AUTOSAR XML (schema 4-2-2)
package /RootP_ASWC_LPhM
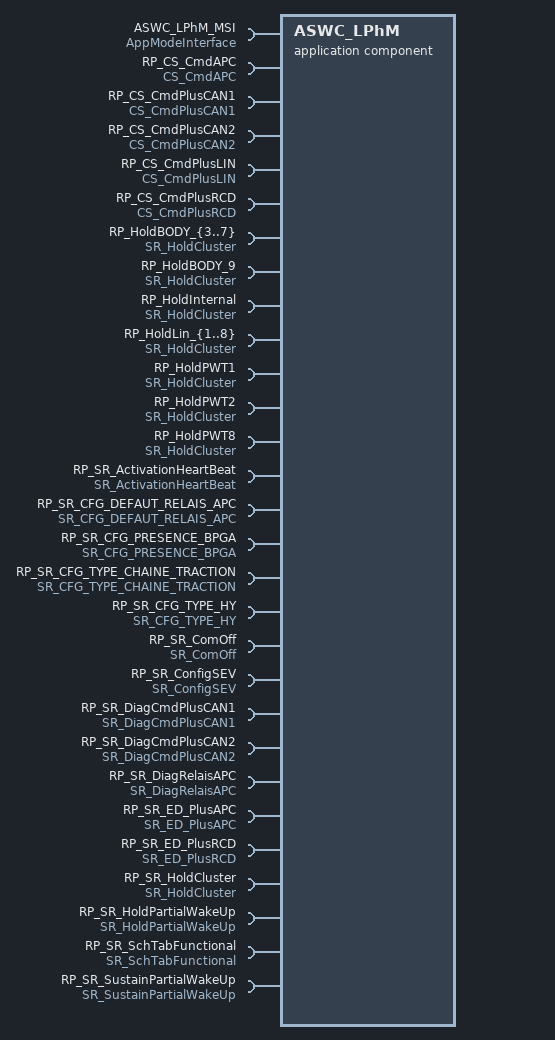
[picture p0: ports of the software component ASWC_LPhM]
  application sw component type ASWC_LPhM
    require port ASWC_LPhM_MSI: required-interface=AppModeInterface
    66 x provide/require port:
      PP_AppModeRequest: nonqueued-receiver-com-spec{data-element=RequestedMode, handle-data-status=true, init-value=CONST_t_ApplicationModeRequestType_0:0}, provided-required-interface=SR_AppModeRequest
      PP_BodyNetworkWkPattern: nonqueued-receiver-com-spec{data-element=CanWkPattern, handle-data-status=true, init-value=CONST_tLOG_0:0}, provided-required-interface=SR_BodyNetworkWkPattern
      PP_BodyVersion: nonqueued-receiver-com-spec{data-element=BodyVersion, handle-data-status=true, init-value=CONST_t_cBodyVersion_0:0}, provided-required-interface=SR_BodyVersion
      PP_ComOffIndicationOnLin: nonqueued-receiver-com-spec{data-element=ComOffIndication, handle-data-status=true, init-value=CONST_ComOffIndication_t_cLIN_COMOFF_cLIN_COMOFFINACTIF:0}, provided-required-interface=SR_ComOffIndicationOnLin
      PP_InhibNetworkWakeUp_CanBody_{3..7}: nonqueued-receiver-com-spec{data-element=NetworkWkInhibition, handle-data-status=true, init-value=CONST_tLOG_0:0}, provided-required-interface=SR_InhibNetworkWakeUp
      PP_InhibNetworkWakeUp_CanBody_9: nonqueued-receiver-com-spec{data-element=NetworkWkInhibition, handle-data-status=true, init-value=CONST_tLOG_0:0}, provided-required-interface=SR_InhibNetworkWakeUp
      PP_InhibPartialWakeUp_CanPwt_1: nonqueued-receiver-com-spec{data-element=PartialWkInhibition, handle-data-status=true, init-value=CONST_tLOG_0:0}, provided-required-interface=SR_InhibPartialWakeUp
      PP_InhibPartialWakeUp_CanPwt_2: nonqueued-receiver-com-spec{data-element=PartialWkInhibition, handle-data-status=true, init-value=CONST_tLOG_0:0}, provided-required-interface=SR_InhibPartialWakeUp
      PP_InhibPartialWakeUp_CanPwt_8: nonqueued-receiver-com-spec{data-element=PartialWkInhibition, handle-data-status=true, init-value=CONST_tLOG_0:0}, provided-required-interface=SR_InhibPartialWakeUp
      PP_LpCanBody_{3..7}: nonqueued-receiver-com-spec{data-element=LpCanBody, handle-data-status=true, init-value=CONST_LpCanBody_t_cLpCanBody_cSGL_BODY_Sleep:0}, provided-required-interface=SR_LpCanBody
      PP_LpCanBody_9: nonqueued-receiver-com-spec{data-element=LpCanBody, handle-data-status=true, init-value=CONST_LpCanBody_t_cLpCanBody_cSGL_BODY_Sleep:0}, provided-required-interface=SR_LpCanBody
      PP_LpLin_{1..8}: nonqueued-receiver-com-spec{data-element=LpLin, handle-data-status=true, init-value=CONST_LpLin_t_cLpLIN_PrepareToSleep:0}, provided-required-interface=SR_LpLin
      PP_NetState_CanBody_{3..7}: nonqueued-receiver-com-spec{data-element=NetState_CanBody, handle-data-status=true, init-value=CONST_NetState_CanBody_t_cCANBODY_cBODY_ComOff:0}, provided-required-interface=SR_NetState_CanBody
      PP_NetState_CanBody_9: nonqueued-receiver-com-spec{data-element=NetState_CanBody, handle-data-status=true, init-value=CONST_NetState_CanBody_t_cCANBODY_cBODY_ComOff:0}, provided-required-interface=SR_NetState_CanBody
      PP_NetState_CanPwt_1: nonqueued-receiver-com-spec{data-element=NetState_CanPwt, handle-data-status=true, init-value=CONST_NetState_CanPwt_t_cCANPWT_cPWT_OFF:0}, provided-required-interface=SR_NetState_CanPwt
      PP_NetState_CanPwt_2: nonqueued-receiver-com-spec{data-element=NetState_CanPwt, handle-data-status=true, init-value=CONST_NetState_CanPwt_t_cCANPWT_cPWT_OFF:0}, provided-required-interface=SR_NetState_CanPwt
      PP_NetState_CanPwt_8: nonqueued-receiver-com-spec{data-element=NetState_CanPwt, handle-data-status=true, init-value=CONST_NetState_CanPwt_t_cCANPWT_cPWT_OFF:0}, provided-required-interface=SR_NetState_CanPwt
      PP_NetState_Lin_{1..8}: nonqueued-receiver-com-spec{data-element=NetState_Lin, handle-data-status=true, init-value=CONST_NetState_Lin_t_cLINLPhM_LIN_SLEEP:0}, provided-required-interface=SR_NetState_Lin
      PP_OpStatusCanPwt_1: nonqueued-receiver-com-spec{data-element=OpStatusCanPwt, handle-data-status=true, init-value=CONST_OpStatusCanPwt_t_cOSPWT_cOSPWT_Default:7}, provided-required-interface=SR_OpStatusCanPwt
      PP_OpStatusCanPwt_2: nonqueued-receiver-com-spec{data-element=OpStatusCanPwt, handle-data-status=true, init-value=CONST_OpStatusCanPwt_t_cOSPWT_cOSPWT_Default:7}, provided-required-interface=SR_OpStatusCanPwt
      PP_OpStatusCanPwt_8: nonqueued-receiver-com-spec{data-element=OpStatusCanPwt, handle-data-status=true, init-value=CONST_OpStatusCanPwt_t_cOSPWT_cOSPWT_Default:7}, provided-required-interface=SR_OpStatusCanPwt
      PRP_SR_AppModeRequest: nonqueued-receiver-com-spec{data-element=RequestedMode, handle-data-status=true, init-value=CONST_t_ApplicationModeRequestType_0:0}, provided-required-interface=SR_AppModeRequest
      PRP_SR_BodyNetworkWkPattern: nonqueued-receiver-com-spec{data-element=CanWkPattern, handle-data-status=true, init-value=CONST_tLOG_0:0}, provided-required-interface=SR_BodyNetworkWkPattern
      PRP_SR_BodyVersion: nonqueued-receiver-com-spec{data-element=BodyVersion, handle-data-status=true, init-value=CONST_t_cBodyVersion_0:0}, provided-required-interface=SR_BodyVersion
      PRP_SR_ComOffIndicationOnLin: nonqueued-receiver-com-spec{data-element=ComOffIndication, handle-data-status=true, init-value=CONST_ComOffIndication_t_cLIN_COMOFF_cLIN_COMOFFINACTIF:0}, provided-required-interface=SR_ComOffIndicationOnLin
      PRP_SR_InhibNetworkWakeUp: nonqueued-receiver-com-spec{data-element=NetworkWkInhibition, handle-data-status=true, init-value=CONST_tLOG_0:0}, provided-required-interface=SR_InhibNetworkWakeUp
      PRP_SR_InhibPartialWakeUp: nonqueued-receiver-com-spec{data-element=PartialWkInhibition, handle-data-status=true, init-value=CONST_tLOG_0:0}, provided-required-interface=SR_InhibPartialWakeUp
      PRP_SR_LastWakeupEvents: nonqueued-receiver-com-spec{data-element=LastWakeupEvents, handle-data-status=true, init-value=CONST_tDWORD_0:0}, provided-required-interface=SR_LastWakeupEvents
      PRP_SR_LpCanBody: nonqueued-receiver-com-spec{data-element=LpCanBody, handle-data-status=true, init-value=CONST_LpCanBody_t_cLpCanBody_cSGL_BODY_Sleep:0}, provided-required-interface=SR_LpCanBody
      PRP_SR_LpLin: nonqueued-receiver-com-spec{data-element=LpLin, handle-data-status=true, init-value=CONST_LpLin_t_cLpLIN_PrepareToSleep:0}, provided-required-interface=SR_LpLin
      PRP_SR_NetState_CanBody: nonqueued-receiver-com-spec{data-element=NetState_CanBody, handle-data-status=true, init-value=CONST_NetState_CanBody_t_cCANBODY_cBODY_ComOff:0}, provided-required-interface=SR_NetState_CanBody
      PRP_SR_NetState_CanPwt: nonqueued-receiver-com-spec{data-element=NetState_CanPwt, handle-data-status=true, init-value=CONST_NetState_CanPwt_t_cCANPWT_cPWT_OFF:0}, provided-required-interface=SR_NetState_CanPwt
      PRP_SR_NetState_Lin: nonqueued-receiver-com-spec{data-element=NetState_Lin, handle-data-status=true, init-value=CONST_NetState_Lin_t_cLINLPhM_LIN_SLEEP:0}, provided-required-interface=SR_NetState_Lin
      PRP_SR_OpStatusCanPwt: nonqueued-receiver-com-spec{data-element=OpStatusCanPwt, handle-data-status=true, init-value=CONST_OpStatusCanPwt_t_cOSPWT_cOSPWT_Default:7}, provided-required-interface=SR_OpStatusCanPwt
      PRP_SR_PwtVersion: nonqueued-receiver-com-spec{data-element=PwtVersion, handle-data-status=true, init-value=CONST_t_cPwtVersion_0:0}, provided-required-interface=SR_PwtVersion
      PRP_SR_StatusCmdAPC: nonqueued-receiver-com-spec{data-element=StatusCmdAPC, handle-data-status=true, init-value=CONST_StatusCmdAPC_t_cCmdAPC_APC_UNDEFINED:0}, provided-required-interface=SR_StatusCmdAPC
      PRP_SR_StatusCmdPlusCAN: nonqueued-receiver-com-spec{data-element=StatusCmdPlusCAN, handle-data-status=true, init-value=CONST_StatusCmdPlusCAN_t_cCmdPlusCAN_PLUSCAN_UNDEFINED:3}, provided-required-interface=SR_StatusCmdPlusCAN
      PRP_SR_StatusCmdPlusLIN: nonqueued-receiver-com-spec{data-element=StatusCmdPlusLIN, handle-data-status=true, init-value=CONST_StatusCmdPlusLIN_t_cCmdPlusLIN_PLUSLIN_UNDEFINED:3}, provided-required-interface=SR_StatusCmdPlusLIN
      PRP_SR_StatusCmdPlusRCD: nonqueued-receiver-com-spec{data-element=StatusCmdPlusRCD, handle-data-status=true, init-value=CONST_StatusCmdPlusRCD_t_cCmdPlusRCD_cPLUSRCD_OFF:0}, provided-required-interface=SR_StatusCmdPlusRCD
      PRP_SR_WakeupCause: nonqueued-receiver-com-spec{data-element=WakeupCause, handle-data-status=true, init-value=CONST_WakeupCause_t_WakeUpCause_cUNKNOWN_SOURCE:0}, provided-required-interface=SR_WakeupCause
    39 x require port:
      RP_CS_CmdAPC: required-interface=CS_CmdAPC
      RP_CS_CmdPlusCAN1: required-interface=CS_CmdPlusCAN1
      RP_CS_CmdPlusCAN2: required-interface=CS_CmdPlusCAN2
      RP_CS_CmdPlusLIN: required-interface=CS_CmdPlusLIN
      RP_CS_CmdPlusRCD: required-interface=CS_CmdPlusRCD
      RP_HoldBODY_{3..7}: nonqueued-receiver-com-spec{data-element=HoldCluster, handle-data-status=true, init-value=CONST_HoldCluster_t_cHOLD_cHOLD_OFF:0}, required-interface=SR_HoldCluster
      RP_HoldBODY_9: nonqueued-receiver-com-spec{data-element=HoldCluster, handle-data-status=true, init-value=CONST_HoldCluster_t_cHOLD_cHOLD_OFF:0}, required-interface=SR_HoldCluster
      RP_HoldInternal: nonqueued-receiver-com-spec{data-element=HoldCluster, handle-data-status=true, init-value=CONST_HoldCluster_t_cHOLD_cHOLD_OFF:0}, required-interface=SR_HoldCluster
      RP_HoldLin_{1..8}: nonqueued-receiver-com-spec{data-element=HoldCluster, handle-data-status=true, init-value=CONST_HoldCluster_t_cHOLD_cHOLD_OFF:0}, required-interface=SR_HoldCluster
      RP_HoldPWT1: nonqueued-receiver-com-spec{data-element=HoldCluster, handle-data-status=true, init-value=CONST_HoldCluster_t_cHOLD_cHOLD_OFF:0}, required-interface=SR_HoldCluster
      RP_HoldPWT2: nonqueued-receiver-com-spec{data-element=HoldCluster, handle-data-status=true, init-value=CONST_HoldCluster_t_cHOLD_cHOLD_OFF:0}, required-interface=SR_HoldCluster
      RP_HoldPWT8: nonqueued-receiver-com-spec{data-element=HoldCluster, handle-data-status=true, init-value=CONST_HoldCluster_t_cHOLD_cHOLD_OFF:0}, required-interface=SR_HoldCluster
      RP_SR_ActivationHeartBeat: nonqueued-receiver-com-spec{data-element=ActivationHeartBeat, handle-data-status=true, init-value=CONST_tLOG_1:1}, required-interface=SR_ActivationHeartBeat
      RP_SR_CFG_DEFAUT_RELAIS_APC: nonqueued-receiver-com-spec{data-element=CFG_DEFAUT_RELAIS_APC, handle-data-status=true, init-value=CONST_tLOG_0:0}, required-interface=SR_CFG_DEFAUT_RELAIS_APC
      RP_SR_CFG_PRESENCE_BPGA: nonqueued-receiver-com-spec{data-element=CFG_PRESENCE_BPGA, handle-data-status=true, init-value=CONST_tLOG_0:0}, required-interface=SR_CFG_PRESENCE_BPGA
      RP_SR_CFG_TYPE_CHAINE_TRACTION: nonqueued-receiver-com-spec{data-element=CFG_TYPE_CHAINE_TRACTION, handle-data-status=true, init-value=CONST_t_cTCT_0:0}, required-interface=SR_CFG_TYPE_CHAINE_TRACTION
      RP_SR_CFG_TYPE_HY: nonqueued-receiver-com-spec{data-element=CFG_TYPE_HY, handle-data-status=true, init-value=CONST_t_H_0:0}, required-interface=SR_CFG_TYPE_HY
      RP_SR_ComOff: nonqueued-receiver-com-spec{data-element=ComOff, handle-data-status=true, init-value=CONST_tLOG_0:0}, required-interface=SR_ComOff
      RP_SR_ConfigSEV: nonqueued-receiver-com-spec{data-element=ConfigSEV, handle-data-status=true, init-value=CONST_ConfigSEV_t_cCSEV_cCSEV_Montage:0}, required-interface=SR_ConfigSEV
      RP_SR_DiagCmdPlusCAN1: nonqueued-receiver-com-spec{data-element=DiagCmdPlusCAN1, handle-data-status=true, init-value=CONST_DiagCmdPlusCAN1_tSDDiag_cSDDiag_DiagOk:0}, required-interface=SR_DiagCmdPlusCAN1
      RP_SR_DiagCmdPlusCAN2: nonqueued-receiver-com-spec{data-element=DiagCmdPlusCAN2, handle-data-status=true, init-value=CONST_DiagCmdPlusCAN2_tSDDiag_cSDDiag_IndispoDiag:2}, required-interface=SR_DiagCmdPlusCAN2
      RP_SR_DiagRelaisAPC: nonqueued-receiver-com-spec{data-element=DiagRelaisAPC, handle-data-status=true, init-value=CONST_tBYTE_0x02:2}, required-interface=SR_DiagRelaisAPC
      RP_SR_ED_PlusAPC: nonqueued-receiver-com-spec{data-element=ED_PlusAPC, handle-data-status=true, init-value=CONST_tLOG_0:0}, required-interface=SR_ED_PlusAPC
      RP_SR_ED_PlusRCD: nonqueued-receiver-com-spec{data-element=ED_PlusRCD, handle-data-status=true, init-value=CONST_tLOG_0:0}, required-interface=SR_ED_PlusRCD
      RP_SR_HoldCluster: nonqueued-receiver-com-spec{data-element=HoldCluster, handle-data-status=true, init-value=CONST_HoldCluster_t_cHOLD_cHOLD_OFF:0}, required-interface=SR_HoldCluster
      RP_SR_HoldPartialWakeUp: required-interface=SR_HoldPartialWakeUp
        required-com-specs:
          data-element=HoldPWT1PartialWakeUp, handle-data-status=true, init-value=CONST_tLOG_0:0
          data-element=HoldPWT2PartialWakeUp, handle-data-status=true, init-value=CONST_tLOG_0:0
          data-element=HoldPWT8PartialWakeUp, handle-data-status=true, init-value=CONST_tLOG_0:0
      RP_SR_SchTabFunctional: required-interface=SR_SchTabFunctional
        required-com-specs:
          data-element=SchTabFunctional_Lin_{1..8}, handle-data-status=true, init-value=CONST_tBYTE_0:0
      RP_SR_SustainPartialWakeUp: required-interface=SR_SustainPartialWakeUp
        required-com-specs:
          data-element=SustainPWT1PartialWakeUp, handle-data-status=true, init-value=CONST_tLOG_0:0
          data-element=SustainPWT2PartialWakeUp, handle-data-status=true, init-value=CONST_tLOG_0:0
          data-element=SustainPWT8PartialWakeUp, handle-data-status=true, init-value=CONST_tLOG_0:0
    behavior IB_ASWC_LPhM: data-type-mapping=ApplicationModeMapping, handle-termination-and-restart=NO-SUPPORT
      data received event HoldPWT1PartialWakeUp_DRE: start-on-event=LPhM_rReceivePartialWakeupPWT_1, data=RP_SR_HoldPartialWakeUp.HoldPWT1PartialWakeUp
      data received event HoldPWT2PartialWakeUp_DRE: start-on-event=LPhM_rReceivePartialWakeupPWT_2, data=RP_SR_HoldPartialWakeUp.HoldPWT2PartialWakeUp
      data received event HoldPWT8PartialWakeUp_DRE: start-on-event=LPhM_rReceivePartialWakeupPWT_8, data=RP_SR_HoldPartialWakeUp.HoldPWT8PartialWakeUp
      swc mode switch event LPhM_rInit_EXIT: start-on-event=LPhM_rInit, activation=ON-EXIT, mode=ASWC_LPhM_MSI.AppMode.APP_WAKEUP
      6 x timing event:
        LPhM_rMain_Cyclic: start-on-event=LPhM_rMain, period=0.01
          disabled-mode:
            ASWC_LPhM_MSI.AppMode.APP_CONFIG
            ASWC_LPhM_MSI.AppMode.APP_OFF
            ASWC_LPhM_MSI.AppMode.APP_SYNC_INIT
            ASWC_LPhM_MSI.AppMode.APP_WAKEUP
        LPhM_rManageAPCDefault_Cyclic: start-on-event=LPhM_rManageAPCDefault, period=0.1
          disabled-mode:
            ASWC_LPhM_MSI.AppMode.APP_CONFIG
            ASWC_LPhM_MSI.AppMode.APP_OFF
            ASWC_LPhM_MSI.AppMode.APP_SYNC_INIT
            ASWC_LPhM_MSI.AppMode.APP_WAKEUP
        LPhM_rManageBodyUnexpectedWUDef_Cyclic: start-on-event=LPhM_rManageBodyUnexpectedWUDef, period=0.01
          disabled-mode:
            ASWC_LPhM_MSI.AppMode.APP_CONFIG
            ASWC_LPhM_MSI.AppMode.APP_OFF
            ASWC_LPhM_MSI.AppMode.APP_SYNC_INIT
            ASWC_LPhM_MSI.AppMode.APP_WAKEUP
        LPhM_rManageCmdPlusCANDefault_Cyclic: start-on-event=LPhM_rManageCmdPlusCANDefault, period=0.1
          disabled-mode:
            ASWC_LPhM_MSI.AppMode.APP_CONFIG
            ASWC_LPhM_MSI.AppMode.APP_OFF
            ASWC_LPhM_MSI.AppMode.APP_SYNC_INIT
            ASWC_LPhM_MSI.AppMode.APP_WAKEUP
        LPhM_rManageLinUnexpectedWUDef_Cyclic: start-on-event=LPhM_rManageLinUnexpectedWUDef, period=0.01
          disabled-mode:
            ASWC_LPhM_MSI.AppMode.APP_CONFIG
            ASWC_LPhM_MSI.AppMode.APP_OFF
            ASWC_LPhM_MSI.AppMode.APP_SYNC_INIT
            ASWC_LPhM_MSI.AppMode.APP_WAKEUP
        LPhM_rManageRcdDefault_Cyclic: start-on-event=LPhM_rManageRcdDefault, period=0.05
          disabled-mode:
            ASWC_LPhM_MSI.AppMode.APP_CONFIG
            ASWC_LPhM_MSI.AppMode.APP_OFF
            ASWC_LPhM_MSI.AppMode.APP_SYNC_INIT
            ASWC_LPhM_MSI.AppMode.APP_WAKEUP
      7 x data send completed event:
        dsce_rMain: start-on-event=LPhM_rMain, event-source=LPhM_rMain/dsp_CanWkPattern
        dsce_rSentWakeupBody_{3..7}: start-on-event=LPhM_rSentWakeupBody_{3..7}, event-source=LPhM_rSentWakeupBody_{3..7}/dsp_CanWkPattern
        dsce_rSentWakeupBody_9: start-on-event=LPhM_rSentWakeupBody_9, event-source=LPhM_rSentWakeupBody_9/dsp_CanWkPattern
      explicit-inter-runnable-variables:
        9 x data, all with type=tLOG, init-value=CONST_tLOG_0:0:
          IRVLPhM_ReceivedPartialWupPwt_1
          IRVLPhM_ReceivedPartialWupPwt_2
          IRVLPhM_ReceivedPartialWupPwt_8
          IRVLPhM_SentWakeupBody{3..7}Notif
          IRVLPhM_SentWakeupBody9Notif
      16 x runnable:
        LPhM_rInit
          data-read-access:
            7 x access:
              dra_PP_ComOffIndicationOnLin_ComOffIndication: accessed-variable=PP_ComOffIndicationOnLin.ComOffIndication
              dra_PP_InhibNetworkWakeUp_CanBody_{3..7}_NetworkWkInhibition: accessed-variable=PP_InhibNetworkWakeUp_CanBody_{3..7}.NetworkWkInhibition
              dra_PP_InhibNetworkWakeUp_CanBody_9_NetworkWkInhibition: accessed-variable=PP_InhibNetworkWakeUp_CanBody_9.NetworkWkInhibition
          data-write-access:
            7 x access:
              dwa_PP_ComOffIndicationOnLin_ComOffIndication: accessed-variable=PP_ComOffIndicationOnLin.ComOffIndication
              dwa_PP_InhibNetworkWakeUp_CanBody_{3..7}_NetworkWkInhibition: accessed-variable=PP_InhibNetworkWakeUp_CanBody_{3..7}.NetworkWkInhibition
              dwa_PP_InhibNetworkWakeUp_CanBody_9_NetworkWkInhibition: accessed-variable=PP_InhibNetworkWakeUp_CanBody_9.NetworkWkInhibition
        LPhM_rMain
          data-read-access:
            97 x access:
              dra_PP_AppModeRequest_RequestedMode: accessed-variable=PP_AppModeRequest.RequestedMode
              dra_PP_BodyNetworkWkPattern_CanWkPattern: accessed-variable=PP_BodyNetworkWkPattern.CanWkPattern
              dra_PP_BodyVersion_BodyVersion: accessed-variable=PP_BodyVersion.BodyVersion
              dra_PP_ComOffIndicationOnLin_ComOffIndication: accessed-variable=PP_ComOffIndicationOnLin.ComOffIndication
              dra_PP_InhibNetworkWakeUp_CanBody_{3..7}_NetworkWkInhibition: accessed-variable=PP_InhibNetworkWakeUp_CanBody_{3..7}.NetworkWkInhibition
              dra_PP_InhibNetworkWakeUp_CanBody_9_NetworkWkInhibition: accessed-variable=PP_InhibNetworkWakeUp_CanBody_9.NetworkWkInhibition
              dra_PP_InhibPartialWakeUp_CanPwt_1_PartialWkInhibition: accessed-variable=PP_InhibPartialWakeUp_CanPwt_1.PartialWkInhibition
              dra_PP_InhibPartialWakeUp_CanPwt_2_PartialWkInhibition: accessed-variable=PP_InhibPartialWakeUp_CanPwt_2.PartialWkInhibition
              dra_PP_InhibPartialWakeUp_CanPwt_8_PartialWkInhibition: accessed-variable=PP_InhibPartialWakeUp_CanPwt_8.PartialWkInhibition
              dra_PP_LpCanBody_{3..7}_LpCanBody: accessed-variable=PP_LpCanBody_{3..7}.LpCanBody
              dra_PP_LpCanBody_9_LpCanBody: accessed-variable=PP_LpCanBody_9.LpCanBody
              dra_PP_LpLin_{1..8}_LpLin: accessed-variable=PP_LpLin_{1..8}.LpLin
              dra_PP_NetState_CanBody_{3..7}_NetState_CanBody: accessed-variable=PP_NetState_CanBody_{3..7}.NetState_CanBody
              dra_PP_NetState_CanBody_9_NetState_CanBody: accessed-variable=PP_NetState_CanBody_9.NetState_CanBody
              dra_PP_NetState_CanPwt_1_NetState_CanPwt: accessed-variable=PP_NetState_CanPwt_1.NetState_CanPwt
              dra_PP_NetState_CanPwt_2_NetState_CanPwt: accessed-variable=PP_NetState_CanPwt_2.NetState_CanPwt
              dra_PP_NetState_CanPwt_8_NetState_CanPwt: accessed-variable=PP_NetState_CanPwt_8.NetState_CanPwt
              dra_PP_NetState_Lin_{1..8}_NetState_Lin: accessed-variable=PP_NetState_Lin_{1..8}.NetState_Lin
              dra_PP_OpStatusCanPwt_1_OpStatusCanPwt: accessed-variable=PP_OpStatusCanPwt_1.OpStatusCanPwt
              dra_PP_OpStatusCanPwt_2_OpStatusCanPwt: accessed-variable=PP_OpStatusCanPwt_2.OpStatusCanPwt
              dra_PP_OpStatusCanPwt_8_OpStatusCanPwt: accessed-variable=PP_OpStatusCanPwt_8.OpStatusCanPwt
              dra_PRP_SR_LastWakeupEvents_LastWakeupEvents: accessed-variable=PRP_SR_LastWakeupEvents.LastWakeupEvents
              dra_PRP_SR_PwtVersion_PwtVersion: accessed-variable=PRP_SR_PwtVersion.PwtVersion
              dra_PRP_SR_StatusCmdAPC_StatusCmdAPC: accessed-variable=PRP_SR_StatusCmdAPC.StatusCmdAPC
              dra_PRP_SR_StatusCmdPlusCAN_StatusCmdPlusCAN: accessed-variable=PRP_SR_StatusCmdPlusCAN.StatusCmdPlusCAN
              dra_PRP_SR_StatusCmdPlusLIN_StatusCmdPlusLIN: accessed-variable=PRP_SR_StatusCmdPlusLIN.StatusCmdPlusLIN
              dra_PRP_SR_StatusCmdPlusRCD_StatusCmdPlusRCD: accessed-variable=PRP_SR_StatusCmdPlusRCD.StatusCmdPlusRCD
              dra_PRP_SR_WakeupCause_WakeupCause: accessed-variable=PRP_SR_WakeupCause.WakeupCause
              dra_RP_HoldBODY_{3..7}_HoldCluster: accessed-variable=RP_HoldBODY_{3..7}.HoldCluster
              dra_RP_HoldBODY_9_HoldCluster: accessed-variable=RP_HoldBODY_9.HoldCluster
              dra_RP_HoldInternal_HoldCluster: accessed-variable=RP_HoldInternal.HoldCluster
              dra_RP_HoldLin_{1..8}_HoldCluster: accessed-variable=RP_HoldLin_{1..8}.HoldCluster
              dra_RP_HoldPWT1_HoldCluster: accessed-variable=RP_HoldPWT1.HoldCluster
              dra_RP_HoldPWT2_HoldCluster: accessed-variable=RP_HoldPWT2.HoldCluster
              dra_RP_HoldPWT8_HoldCluster: accessed-variable=RP_HoldPWT8.HoldCluster
              dra_RP_SR_ActivationHeartBeat_ActivationHeartBeat: accessed-variable=RP_SR_ActivationHeartBeat.ActivationHeartBeat
              dra_RP_SR_CFG_PRESENCE_BPGA_CFG_PRESENCE_BPGA: accessed-variable=RP_SR_CFG_PRESENCE_BPGA.CFG_PRESENCE_BPGA
              dra_RP_SR_CFG_TYPE_CHAINE_TRACTION_CFG_TYPE_CHAINE_TRACTION: accessed-variable=RP_SR_CFG_TYPE_CHAINE_TRACTION.CFG_TYPE_CHAINE_TRACTION
              dra_RP_SR_CFG_TYPE_HY_CFG_TYPE_HY: accessed-variable=RP_SR_CFG_TYPE_HY.CFG_TYPE_HY
              dra_RP_SR_ComOff_ComOff: accessed-variable=RP_SR_ComOff.ComOff
              dra_RP_SR_ConfigSEV_ConfigSEV: accessed-variable=RP_SR_ConfigSEV.ConfigSEV
              dra_RP_SR_DiagCmdPlusCAN1_DiagCmdPlusCAN1: accessed-variable=RP_SR_DiagCmdPlusCAN1.DiagCmdPlusCAN1
              dra_RP_SR_DiagCmdPlusCAN2_DiagCmdPlusCAN2: accessed-variable=RP_SR_DiagCmdPlusCAN2.DiagCmdPlusCAN2
              dra_RP_SR_DiagRelaisAPC_DiagRelaisAPC: accessed-variable=RP_SR_DiagRelaisAPC.DiagRelaisAPC
              dra_RP_SR_ED_PlusAPC_ED_PlusAPC: accessed-variable=RP_SR_ED_PlusAPC.ED_PlusAPC
              dra_RP_SR_ED_PlusRCD_ED_PlusRCD: accessed-variable=RP_SR_ED_PlusRCD.ED_PlusRCD
              dra_RP_SR_HoldPartialWakeUp_HoldPWT1PartialWakeUp: accessed-variable=RP_SR_HoldPartialWakeUp.HoldPWT1PartialWakeUp
              dra_RP_SR_HoldPartialWakeUp_HoldPWT2PartialWakeUp: accessed-variable=RP_SR_HoldPartialWakeUp.HoldPWT2PartialWakeUp
              dra_RP_SR_HoldPartialWakeUp_HoldPWT8PartialWakeUp: accessed-variable=RP_SR_HoldPartialWakeUp.HoldPWT8PartialWakeUp
              dra_RP_SR_SchTabFunctional_SchTabFunctional_Lin_{1..8}: accessed-variable=RP_SR_SchTabFunctional.SchTabFunctional_Lin_{1..8}
              dra_RP_SR_SustainPartialWakeUp_SustainPWT1PartialWakeUp: accessed-variable=RP_SR_SustainPartialWakeUp.SustainPWT1PartialWakeUp
              dra_RP_SR_SustainPartialWakeUp_SustainPWT2PartialWakeUp: accessed-variable=RP_SR_SustainPartialWakeUp.SustainPWT2PartialWakeUp
              dra_RP_SR_SustainPartialWakeUp_SustainPWT8PartialWakeUp: accessed-variable=RP_SR_SustainPartialWakeUp.SustainPWT8PartialWakeUp
          data-send-points:
            access dsp_CanWkPattern: accessed-variable=PP_BodyNetworkWkPattern.CanWkPattern
          data-write-access:
            54 x access:
              dwa_PP_AppModeRequest_RequestedMode: accessed-variable=PP_AppModeRequest.RequestedMode
              dwa_PP_BodyNetworkWkPattern_CanWkPattern: accessed-variable=PP_BodyNetworkWkPattern.CanWkPattern
              dwa_PP_BodyVersion_BodyVersion: accessed-variable=PP_BodyVersion.BodyVersion
              dwa_PP_ComOffIndicationOnLin_ComOffIndication: accessed-variable=PP_ComOffIndicationOnLin.ComOffIndication
              dwa_PP_InhibNetworkWakeUp_CanBody_{3..7}_NetworkWkInhibition: accessed-variable=PP_InhibNetworkWakeUp_CanBody_{3..7}.NetworkWkInhibition
              dwa_PP_InhibNetworkWakeUp_CanBody_9_NetworkWkInhibition: accessed-variable=PP_InhibNetworkWakeUp_CanBody_9.NetworkWkInhibition
              dwa_PP_InhibPartialWakeUp_CanPwt_1_PartialWkInhibition: accessed-variable=PP_InhibPartialWakeUp_CanPwt_1.PartialWkInhibition
              dwa_PP_InhibPartialWakeUp_CanPwt_2_PartialWkInhibition: accessed-variable=PP_InhibPartialWakeUp_CanPwt_2.PartialWkInhibition
              dwa_PP_InhibPartialWakeUp_CanPwt_8_PartialWkInhibition: accessed-variable=PP_InhibPartialWakeUp_CanPwt_8.PartialWkInhibition
              dwa_PP_LpCanBody_{3..7}_LpCanBody: accessed-variable=PP_LpCanBody_{3..7}.LpCanBody
              dwa_PP_LpCanBody_9_LpCanBody: accessed-variable=PP_LpCanBody_9.LpCanBody
              dwa_PP_LpLin_{1..8}_LpLin: accessed-variable=PP_LpLin_{1..8}.LpLin
              dwa_PP_NetState_CanBody_{3..7}_NetState_CanBody: accessed-variable=PP_NetState_CanBody_{3..7}.NetState_CanBody
              dwa_PP_NetState_CanBody_9_NetState_CanBody: accessed-variable=PP_NetState_CanBody_9.NetState_CanBody
              dwa_PP_NetState_CanPwt_1_NetState_CanPwt: accessed-variable=PP_NetState_CanPwt_1.NetState_CanPwt
              dwa_PP_NetState_CanPwt_2_NetState_CanPwt: accessed-variable=PP_NetState_CanPwt_2.NetState_CanPwt
              dwa_PP_NetState_CanPwt_8_NetState_CanPwt: accessed-variable=PP_NetState_CanPwt_8.NetState_CanPwt
              dwa_PP_NetState_Lin_{1..8}_NetState_Lin: accessed-variable=PP_NetState_Lin_{1..8}.NetState_Lin
              dwa_PP_OpStatusCanPwt_1_OpStatusCanPwt: accessed-variable=PP_OpStatusCanPwt_1.OpStatusCanPwt
              dwa_PP_OpStatusCanPwt_2_OpStatusCanPwt: accessed-variable=PP_OpStatusCanPwt_2.OpStatusCanPwt
              dwa_PP_OpStatusCanPwt_8_OpStatusCanPwt: accessed-variable=PP_OpStatusCanPwt_8.OpStatusCanPwt
              dwa_PRP_SR_LastWakeupEvents_LastWakeupEvents: accessed-variable=PRP_SR_LastWakeupEvents.LastWakeupEvents
              dwa_PRP_SR_PwtVersion_PwtVersion: accessed-variable=PRP_SR_PwtVersion.PwtVersion
              dwa_PRP_SR_StatusCmdAPC_StatusCmdAPC: accessed-variable=PRP_SR_StatusCmdAPC.StatusCmdAPC
              dwa_PRP_SR_StatusCmdPlusCAN_StatusCmdPlusCAN: accessed-variable=PRP_SR_StatusCmdPlusCAN.StatusCmdPlusCAN
              dwa_PRP_SR_StatusCmdPlusLIN_StatusCmdPlusLIN: accessed-variable=PRP_SR_StatusCmdPlusLIN.StatusCmdPlusLIN
              dwa_PRP_SR_StatusCmdPlusRCD_StatusCmdPlusRCD: accessed-variable=PRP_SR_StatusCmdPlusRCD.StatusCmdPlusRCD
              dwa_PRP_SR_WakeupCause_WakeupCause: accessed-variable=PRP_SR_WakeupCause.WakeupCause
          read-local-variables:
            9 x access:
              rlv_IRVLPhM_ReceivedPartialWupPwt_1: accessed-variable=IRVLPhM_ReceivedPartialWupPwt_1
              rlv_IRVLPhM_ReceivedPartialWupPwt_2: accessed-variable=IRVLPhM_ReceivedPartialWupPwt_2
              rlv_IRVLPhM_ReceivedPartialWupPwt_8: accessed-variable=IRVLPhM_ReceivedPartialWupPwt_8
              rlv_IRVLPhM_SentWakeupBody{3..7}Notif: accessed-variable=IRVLPhM_SentWakeupBody{3..7}Notif
              rlv_IRVLPhM_SentWakeupBody9Notif: accessed-variable=IRVLPhM_SentWakeupBody9Notif
          5 x sync call, all with timeout=0.0:
            sscp_LPhM_rMain_CS_CmdAPC_Set: operation=RP_CS_CmdAPC.Set
            sscp_LPhM_rMain_CS_CmdPlusCAN1_Set: operation=RP_CS_CmdPlusCAN1.Set
            sscp_LPhM_rMain_CS_CmdPlusCAN2_Set: operation=RP_CS_CmdPlusCAN2.Set
            sscp_LPhM_rMain_CS_CmdPlusLIN_Set: operation=RP_CS_CmdPlusLIN.Set
            sscp_LPhM_rMain_CS_CmdPlusRCD_Set: operation=RP_CS_CmdPlusRCD.Set
          written-local-variables:
            9 x access:
              wlv_IRVLPhM_ReceivedPartialWupPwt_1: accessed-variable=IRVLPhM_ReceivedPartialWupPwt_1
              wlv_IRVLPhM_ReceivedPartialWupPwt_2: accessed-variable=IRVLPhM_ReceivedPartialWupPwt_2
              wlv_IRVLPhM_ReceivedPartialWupPwt_8: accessed-variable=IRVLPhM_ReceivedPartialWupPwt_8
              wlv_IRVLPhM_SentWakeupBody{3..7}Notif: accessed-variable=IRVLPhM_SentWakeupBody{3..7}Notif
              wlv_IRVLPhM_SentWakeupBody9Notif: accessed-variable=IRVLPhM_SentWakeupBody9Notif
        LPhM_rManageAPCDefault
          data-read-access:
            access dra_PRP_SR_StatusCmdAPC_StatusCmdAPC: accessed-variable=PRP_SR_StatusCmdAPC.StatusCmdAPC
            access dra_RP_SR_CFG_DEFAUT_RELAIS_APC_CFG_DEFAUT_RELAIS_APC: accessed-variable=RP_SR_CFG_DEFAUT_RELAIS_APC.CFG_DEFAUT_RELAIS_APC
            access dra_RP_SR_DiagRelaisAPC_DiagRelaisAPC: accessed-variable=RP_SR_DiagRelaisAPC.DiagRelaisAPC
        LPhM_rManageBodyUnexpectedWUDef
        LPhM_rManageCmdPlusCANDefault
          data-read-access:
            access dra_PRP_SR_StatusCmdPlusCAN_StatusCmdPlusCAN: accessed-variable=PRP_SR_StatusCmdPlusCAN.StatusCmdPlusCAN
            access dra_RP_SR_DiagCmdPlusCAN1_DiagCmdPlusCAN1: accessed-variable=RP_SR_DiagCmdPlusCAN1.DiagCmdPlusCAN1
            access dra_RP_SR_DiagCmdPlusCAN2_DiagCmdPlusCAN2: accessed-variable=RP_SR_DiagCmdPlusCAN2.DiagCmdPlusCAN2
        LPhM_rManageLinUnexpectedWUDef
        LPhM_rManageRcdDefault
          data-read-access:
            access dra_PRP_SR_StatusCmdPlusRCD_StatusCmdPlusRCD: accessed-variable=PRP_SR_StatusCmdPlusRCD.StatusCmdPlusRCD
            access dra_RP_SR_ED_PlusRCD_ED_PlusRCD: accessed-variable=RP_SR_ED_PlusRCD.ED_PlusRCD
        LPhM_rReceivePartialWakeupPWT_1
          read-local-variables:
            access rlv_IRVLPhM_ReceivedPartialWupPwt_1: accessed-variable=IRVLPhM_ReceivedPartialWupPwt_1
          written-local-variables:
            access wlv_IRVLPhM_ReceivedPartialWupPwt_1: accessed-variable=IRVLPhM_ReceivedPartialWupPwt_1
        LPhM_rReceivePartialWakeupPWT_2
          read-local-variables:
            access rlv_IRVLPhM_ReceivedPartialWupPwt_2: accessed-variable=IRVLPhM_ReceivedPartialWupPwt_2
          written-local-variables:
            access wlv_IRVLPhM_ReceivedPartialWupPwt_2: accessed-variable=IRVLPhM_ReceivedPartialWupPwt_2
        LPhM_rReceivePartialWakeupPWT_8
          read-local-variables:
            access rlv_IRVLPhM_ReceivedPartialWupPwt_8: accessed-variable=IRVLPhM_ReceivedPartialWupPwt_8
          written-local-variables:
            access wlv_IRVLPhM_ReceivedPartialWupPwt_8: accessed-variable=IRVLPhM_ReceivedPartialWupPwt_8
        LPhM_rSentWakeupBody_3
          data-receive-point-by-arguments:
            access drparg_CanWkPattern: accessed-variable=PP_BodyNetworkWkPattern.CanWkPattern
          data-send-points:
            access dsp_CanWkPattern: accessed-variable=PP_BodyNetworkWkPattern.CanWkPattern
          read-local-variables:
            access rlv_IRVLPhM_SentWakeupBody3Notif: accessed-variable=IRVLPhM_SentWakeupBody3Notif
          written-local-variables:
            access wlv_IRVLPhM_SentWakeupBody3Notif: accessed-variable=IRVLPhM_SentWakeupBody3Notif
        LPhM_rSentWakeupBody_4
          data-receive-point-by-arguments:
            access drparg_CanWkPattern: accessed-variable=PP_BodyNetworkWkPattern.CanWkPattern
          data-send-points:
            access dsp_CanWkPattern: accessed-variable=PP_BodyNetworkWkPattern.CanWkPattern
          read-local-variables:
            access rlv_IRVLPhM_SentWakeupBody4Notif: accessed-variable=IRVLPhM_SentWakeupBody4Notif
          written-local-variables:
            access wlv_IRVLPhM_SentWakeupBody4Notif: accessed-variable=IRVLPhM_SentWakeupBody4Notif
        LPhM_rSentWakeupBody_5
          data-receive-point-by-arguments:
            access drparg_CanWkPattern: accessed-variable=PP_BodyNetworkWkPattern.CanWkPattern
          data-send-points:
            access dsp_CanWkPattern: accessed-variable=PP_BodyNetworkWkPattern.CanWkPattern
          read-local-variables:
            access rlv_IRVLPhM_SentWakeupBody5Notif: accessed-variable=IRVLPhM_SentWakeupBody5Notif
          written-local-variables:
            access wlv_IRVLPhM_SentWakeupBody5Notif: accessed-variable=IRVLPhM_SentWakeupBody5Notif
        LPhM_rSentWakeupBody_6
          data-receive-point-by-arguments:
            access drparg_CanWkPattern: accessed-variable=PP_BodyNetworkWkPattern.CanWkPattern
          data-send-points:
            access dsp_CanWkPattern: accessed-variable=PP_BodyNetworkWkPattern.CanWkPattern
          read-local-variables:
            access rlv_IRVLPhM_SentWakeupBody6Notif: accessed-variable=IRVLPhM_SentWakeupBody6Notif
          written-local-variables:
            access wlv_IRVLPhM_SentWakeupBody6Notif: accessed-variable=IRVLPhM_SentWakeupBody6Notif
        LPhM_rSentWakeupBody_7
          data-receive-point-by-arguments:
            access drparg_CanWkPattern: accessed-variable=PP_BodyNetworkWkPattern.CanWkPattern
          data-send-points:
            access dsp_CanWkPattern: accessed-variable=PP_BodyNetworkWkPattern.CanWkPattern
          read-local-variables:
            access rlv_IRVLPhM_SentWakeupBody7Notif: accessed-variable=IRVLPhM_SentWakeupBody7Notif
          written-local-variables:
            access wlv_IRVLPhM_SentWakeupBody7Notif: accessed-variable=IRVLPhM_SentWakeupBody7Notif
        LPhM_rSentWakeupBody_9
          data-receive-point-by-arguments:
            access drparg_CanWkPattern: accessed-variable=PP_BodyNetworkWkPattern.CanWkPattern
          data-send-points:
            access dsp_CanWkPattern: accessed-variable=PP_BodyNetworkWkPattern.CanWkPattern
          read-local-variables:
            access rlv_IRVLPhM_SentWakeupBody9Notif: accessed-variable=IRVLPhM_SentWakeupBody9Notif
          written-local-variables:
            access wlv_IRVLPhM_SentWakeupBody9Notif: accessed-variable=IRVLPhM_SentWakeupBody9Notif
package /RootP_Implementatation
  swc implementation Implementatation_ASWC_LPhM: programming-language=C, sw-version=1.0.0, vendor-id=1, behavior=IB_ASWC_LPhM
    code-descriptors:
      code SRC: artifact-descriptors=autosar-engineering-object={short-label=EngObject, category=SWSRC}
    resource consumption Resources
